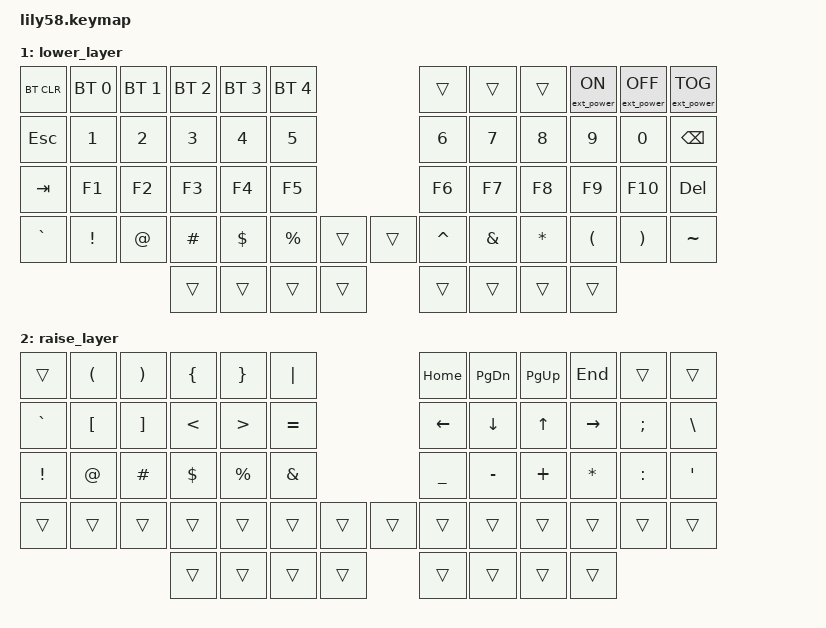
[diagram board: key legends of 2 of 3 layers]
/*
 * Copyright (c) 2020 The ZMK Contributors
 *
 * SPDX-License-Identifier: MIT
 */

#include <behaviors.dtsi>
#include <dt-bindings/zmk/keys.h>
#include <dt-bindings/zmk/bt.h>
#include <dt-bindings/zmk/ext_power.h>

/ {
    keymap {
        compatible = "zmk,keymap";

        default_layer {
// ------------------------------------------------------------------------------------------------------------
// |  ESC  |  1  |  2  |  3   |  4   |  5   |                   |  6   |  7    |  8    |  9   |   0   |   `   |
// |  TAB  |  Q  |  W  |  E   |  R   |  T   |                   |  Y   |  U    |  I    |  O   |   P   |   -   |
// |  CTRL |  A  |  S  |  D   |  F   |  G   |                   |  H   |  J    |  K    |  L   |   ;   |   '   |
// | SHIFT |  Z  |  X  |  C   |  V   |  B   |   "["  |  |  "]"  |  N   |  M    |  ,    |  .   |   /   | SHIFT |
//                     | ALT  | GUI  | LOWER|  SPACE |  | ENTER | RAISE| BSPC  | GUI   |
            bindings = <
&kp ESC   &kp N1 &kp N2 &kp N3   &kp N4   &kp N5                     &kp N6 &kp N7   &kp N8    &kp N9  &kp N0   &kp GRAVE
&kp TAB   &kp Q  &kp W  &kp E    &kp R    &kp T                      &kp Y  &kp U    &kp I     &kp O   &kp P    &kp MINUS
&kp LCTRL &kp A  &kp S  &kp D    &kp F    &kp G                      &kp H  &kp J    &kp K     &kp L   &kp SEMI &kp SQT
&kp LSHFT &kp Z  &kp X  &kp C    &kp V    &kp B  &kp LBKT   &kp RBKT &kp N  &kp M    &kp COMMA &kp DOT &kp FSLH &kp RSHFT
                        &kp LALT &kp LGUI &lt 1 SPACE &lt 2 RET   &kp BSPC &kp DEL  &kp RGUI
            >;

            sensor-bindings = <&inc_dec_kp C_VOL_UP C_VOL_DN>;
        };

        lower_layer {
// ------------------------------------------------------------------------------------------------------------
// Layer 1 (NUM): numbers, function keys, and BT profile switching
// | BTCLR |  BT1 |  BT2 |  BT3 |  BT4 |  BT5 |                   |      |      |      |      |      |      |
// |  ESC  |   1  |   2  |   3  |   4  |   5  |                   |   6  |   7  |   8  |   9  |   0  | BSPC |
// |  TAB  |  F1  |  F2  |  F3  |  F4  |  F5  |                   |  F6  |  F7  |  F8  |  F9  | F10  |  DEL |
// |  `    |  !   |  @   |  #   |  $   |  %   |        |  |       |  ^   |  &   |  *   |  (   |  )   |  ~   |
//                     |      |      |      |        |  |       |      |      |      |
            bindings = <
&bt BT_CLR &bt BT_SEL 0 &bt BT_SEL 1 &bt BT_SEL 2 &bt BT_SEL 3 &bt BT_SEL 4                 &trans   &trans  &trans  &ext_power EP_ON &ext_power EP_OFF &ext_power EP_TOG
&kp ESC    &kp N1       &kp N2       &kp N3       &kp N4       &kp N5                         &kp N6   &kp N7  &kp N8  &kp N9  &kp N0  &kp BSPC
&kp TAB    &kp F1       &kp F2       &kp F3       &kp F4       &kp F5                         &kp F6   &kp F7  &kp F8  &kp F9  &kp F10 &kp DEL
&kp GRAVE  &kp EXCL     &kp AT       &kp HASH     &kp DOLLAR   &kp PRCNT   &trans   &trans    &kp CARET &kp AMPS &kp ASTRK &kp LPAR &kp RPAR &kp TILDE
                               &trans         &trans       &trans     &trans    &trans    &trans    &trans    &trans
                >;

            sensor-bindings = <&inc_dec_kp C_VOL_UP C_VOL_DN>;
        };

        raise_layer {
// ------------------------------------------------------------------------------------------------------------
// Layer 2 (SYM/NAV): coding symbols + navigation (great for Java/SQL/terminal)
// |      |  (   |  )   |  {   |  }   |  |   |                   | HOME | PGDN | PGUP | END  |      |      |
// |  `   |  [   |  ]   |  <   |  >   |  =   |                   |  <-  |  v   |  ^   |  ->  |  ;   |  \\  |
// |  !   |  @   |  #   |  $   |  %   |  &   |                   |  _   |  -   |  +   |  *   |  :   |  '   |
// |      |      |      |      |      |      |        |  |       |      |      |      |      |      |      |
//                     |      |      |      |        |  |       |      |      |      |
            bindings = <
&trans     &kp LPAR  &kp RPAR  &kp LBRC  &kp RBRC  &kp PIPE                     &kp HOME &kp PG_DN &kp PG_UP &kp END  &trans     &trans
&kp GRAVE  &kp LBKT  &kp RBKT  &kp LT    &kp GT    &kp EQUAL                    &kp LEFT &kp DOWN  &kp UP    &kp RIGHT &kp SEMI   &kp BSLH
&kp EXCL   &kp AT    &kp HASH  &kp DOLLAR &kp PRCNT &kp AMPS                    &kp UNDER &kp MINUS &kp PLUS  &kp STAR  &kp COLON  &kp SQT
&trans     &trans    &trans    &trans    &trans    &trans    &trans   &trans    &trans    &trans    &trans    &trans    &trans     &trans
                                   &trans          &trans      &trans &trans    &trans   &trans    &trans    &trans
            >;

            sensor-bindings = <&inc_dec_kp C_VOL_UP C_VOL_DN>;
        };
    };
};
